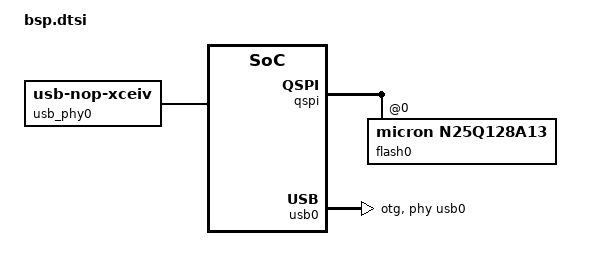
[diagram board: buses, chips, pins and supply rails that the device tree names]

&qspi {
	flash0: flash@0 {
		compatible = "micron,n25q128a13";
	};
};

/ {
    usb_phy0:usb_phy@0 {
        compatible="usb-nop-xceiv";
        #phy-cells = <0>;
    };
};


&usb0 {
	dr_mode = "otg";
	usb-phy = <&usb0>;
};

